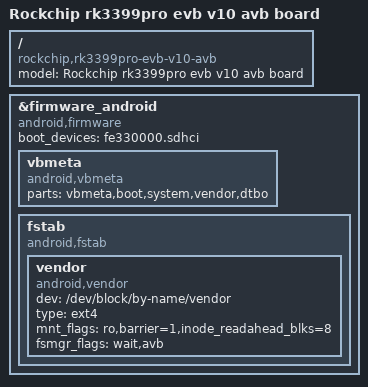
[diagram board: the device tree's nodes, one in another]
// SPDX-License-Identifier: (GPL-2.0+ OR MIT)
/*
 * Copyright (c) 2018 Fuzhou Rockchip Electronics Co., Ltd
 *
 */

/dts-v1/;
#include "rk3399pro-evb-v10.dtsi"

/ {
	model = "Rockchip rk3399pro evb v10 avb board";
	compatible = "rockchip,rk3399pro-evb-v10-avb", "rockchip,rk3399pro";
};

&firmware_android {
	compatible = "android,firmware";
	boot_devices = "fe330000.sdhci";
	vbmeta {
		compatible = "android,vbmeta";
		parts = "vbmeta,boot,system,vendor,dtbo";
	};
	fstab {
		compatible = "android,fstab";
		vendor {
			compatible = "android,vendor";
			dev = "/dev/block/by-name/vendor";
			type = "ext4";
			mnt_flags = "ro,barrier=1,inode_readahead_blks=8";
			fsmgr_flags = "wait,avb";
		};
	};
};
